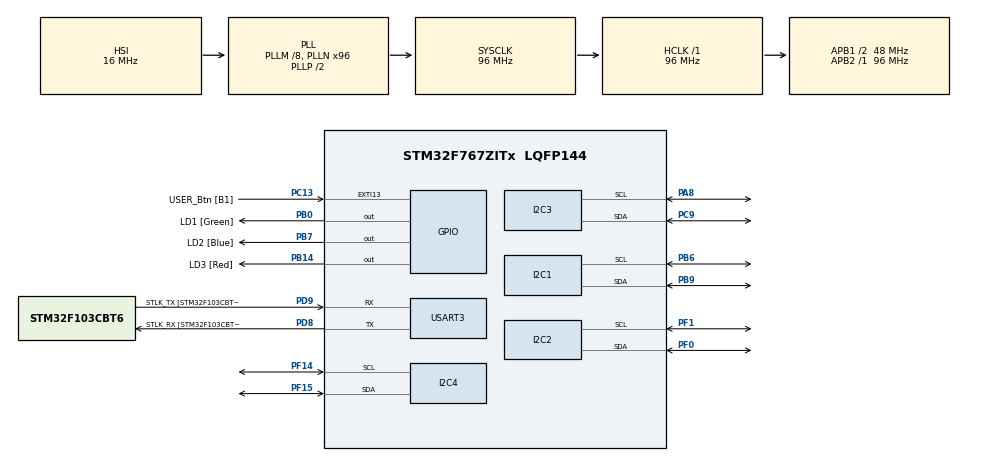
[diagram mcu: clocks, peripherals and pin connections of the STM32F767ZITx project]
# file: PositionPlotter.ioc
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CORTEX_M7.default_mode_Activation=1
Dma.I2C1_RX.0.Direction=DMA_PERIPH_TO_MEMORY
Dma.I2C1_RX.0.FIFOMode=DMA_FIFOMODE_DISABLE
Dma.I2C1_RX.0.Instance=DMA1_Stream0
Dma.I2C1_RX.0.MemDataAlignment=DMA_MDATAALIGN_BYTE
Dma.I2C1_RX.0.MemInc=DMA_MINC_ENABLE
Dma.I2C1_RX.0.Mode=DMA_NORMAL
Dma.I2C1_RX.0.PeriphDataAlignment=DMA_PDATAALIGN_BYTE
Dma.I2C1_RX.0.PeriphInc=DMA_PINC_DISABLE
Dma.I2C1_RX.0.Priority=DMA_PRIORITY_LOW
Dma.I2C2_RX.1.Direction=DMA_PERIPH_TO_MEMORY
Dma.I2C2_RX.1.FIFOMode=DMA_FIFOMODE_DISABLE
Dma.I2C2_RX.1.Instance=DMA1_Stream3
Dma.I2C2_RX.1.MemDataAlignment=DMA_MDATAALIGN_BYTE
Dma.I2C2_RX.1.MemInc=DMA_MINC_ENABLE
Dma.I2C2_RX.1.Mode=DMA_NORMAL
Dma.I2C2_RX.1.PeriphDataAlignment=DMA_PDATAALIGN_BYTE
Dma.I2C2_RX.1.PeriphInc=DMA_PINC_DISABLE
Dma.I2C2_RX.1.Priority=DMA_PRIORITY_LOW
Dma.I2C3_RX.2.Direction=DMA_PERIPH_TO_MEMORY
Dma.I2C3_RX.2.FIFOMode=DMA_FIFOMODE_DISABLE
Dma.I2C3_RX.2.Instance=DMA1_Stream2
Dma.I2C3_RX.2.MemDataAlignment=DMA_MDATAALIGN_BYTE
Dma.I2C3_RX.2.MemInc=DMA_MINC_ENABLE
Dma.I2C3_RX.2.Mode=DMA_NORMAL
Dma.I2C3_RX.2.PeriphDataAlignment=DMA_PDATAALIGN_BYTE
Dma.I2C3_RX.2.PeriphInc=DMA_PINC_DISABLE
Dma.I2C3_RX.2.Priority=DMA_PRIORITY_LOW
Dma.I2C4_RX.3.Direction=DMA_PERIPH_TO_MEMORY
Dma.I2C4_RX.3.FIFOMode=DMA_FIFOMODE_DISABLE
Dma.I2C4_RX.3.Instance=DMA1_Stream1
Dma.I2C4_RX.3.MemDataAlignment=DMA_MDATAALIGN_BYTE
Dma.I2C4_RX.3.MemInc=DMA_MINC_ENABLE
Dma.I2C4_RX.3.Mode=DMA_NORMAL
Dma.I2C4_RX.3.PeriphDataAlignment=DMA_PDATAALIGN_BYTE
Dma.I2C4_RX.3.PeriphInc=DMA_PINC_DISABLE
Dma.I2C4_RX.3.Priority=DMA_PRIORITY_LOW
Dma.Request0=I2C1_RX
Dma.Request1=I2C2_RX
Dma.Request2=I2C3_RX
Dma.Request3=I2C4_RX
I2C1.Timing=0x20303E5D
I2C2.Timing=0x20303E5D
I2C3.Timing=0x20303E5D
I2C4.Timing=0x20303E5D
Mcu.Family=STM32F7
Mcu.Name=STM32F767ZITx
Mcu.Package=LQFP144
NVIC.DMA1_Stream0_IRQn=true\:0\:0\:false\:false\:true\:false\:true\:true
NVIC.DMA1_Stream1_IRQn=true\:0\:0\:false\:false\:true\:false\:true\:true
NVIC.DMA1_Stream2_IRQn=true\:0\:0\:false\:false\:true\:false\:true\:true
NVIC.DMA1_Stream3_IRQn=true\:0\:0\:false\:false\:true\:false\:true\:true
NVIC.PriorityGroup=NVIC_PRIORITYGROUP_4
NVIC.TIM1_UP_TIM10_IRQn=true\:0\:0\:false\:false\:true\:true\:true\:true
PA8.Mode=I2C
PA8.Signal=I2C3_SCL
PB0.GPIO_Label=LD1 [Green]
PB0.Signal=GPIO_Output
PB14.GPIO_Label=LD3 [Red]
PB14.Signal=GPIO_Output
PB6.Mode=I2C
PB6.Signal=I2C1_SCL
PB7.GPIO_Label=LD2 [Blue]
PB7.Signal=GPIO_Output
PB9.Mode=I2C
PB9.Signal=I2C1_SDA
PC13.GPIO_Label=USER_Btn [B1]
PC13.Signal=GPXTI13
PC14/OSC32_IN.Mode=LSE-External-Oscillator
PC14/OSC32_IN.Signal=RCC_OSC32_IN
PC15/OSC32_OUT.Mode=LSE-External-Oscillator
PC15/OSC32_OUT.Signal=RCC_OSC32_OUT
PC9.Mode=I2C
PC9.Signal=I2C3_SDA
PD8.GPIO_Label=STLK_RX [STM32F103CBT6_PA3]
PD8.Mode=Asynchronous
PD8.Signal=USART3_TX
PD9.GPIO_Label=STLK_TX [STM32F103CBT6_PA2]
PD9.Mode=Asynchronous
PD9.Signal=USART3_RX
PF0.Mode=I2C
PF0.Signal=I2C2_SDA
PF1.Mode=I2C
PF1.Signal=I2C2_SCL
PF14.Mode=I2C
PF14.Signal=I2C4_SCL
PF15.Mode=I2C
PF15.Signal=I2C4_SDA
ProjectManager.HeapSize=0x200
ProjectManager.StackSize=0x400
ProjectManager.TargetToolchain=STM32CubeIDE
RCC.48MHZClocksFreq_Value=24000000
RCC.AHBFreq_Value=96000000
RCC.APB1CLKDivider=RCC_HCLK_DIV2
RCC.APB1Freq_Value=48000000
RCC.APB1TimFreq_Value=96000000
RCC.APB2Freq_Value=96000000
RCC.APB2TimFreq_Value=96000000
RCC.CortexFreq_Value=96000000
RCC.HCLKFreq_Value=96000000
RCC.HSE_VALUE=8000000
RCC.HSI_VALUE=16000000
RCC.PLLM=8
RCC.PLLMUL=RCC_PLL_MUL9
RCC.PLLN=96
RCC.PLLQ=4
RCC.PRESCALERUSB=RCC_USBCLKSOURCE_PLL_DIV1_5
RCC.SYSCLKFreq_VALUE=96000000
RCC.SYSCLKSource=RCC_SYSCLKSOURCE_PLLCLK
RCC.SYSCLKSourceVirtual=RCC_SYSCLKSOURCE_PLLCLK
RCC.USBFreq_Value=48000000
RCC.VCOOutputFreq_Value=192000000
USART3.VirtualMode-Asynchronous=VM_ASYNC
VP_TIM1_VS_ClockSourceINT.Mode=Internal
board=NUCLEO-F767ZI

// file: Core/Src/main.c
/* USER CODE BEGIN Header */
/**
  ******************************************************************************
  * @file           : main.c
  * @brief          : Main program body
  ******************************************************************************
  * @attention
  *
  * Copyright (c) 2026 STMicroelectronics.
  * All rights reserved.
  *
  * This software is licensed under terms that can be found in the LICENSE file
  * in the root directory of this software component.
  * If no LICENSE file comes with this software, it is provided AS-IS.
  *
  ******************************************************************************
  */
/* USER CODE END Header */
#include "main.h"
#include "dma.h"
#include "i2c.h"
#include "tim.h"
#include "usart.h"
#include "gpio.h"

/* USER CODE BEGIN Includes */
#include "encplot_main.h"
/* USER CODE END Includes */

void SystemClock_Config(void);
static void MPU_Config(void);

int main(void)
{

  /* MPU Configuration--------------------------------------------------------*/
  MPU_Config();

  /* MCU Configuration--------------------------------------------------------*/

  /* Reset of all peripherals, Initializes the Flash interface and the Systick. */
  HAL_Init();

  /* Configure the system clock */
  SystemClock_Config();

  /* Initialize all configured peripherals */
  MX_GPIO_Init();
  MX_DMA_Init();
  MX_I2C1_Init();
  MX_I2C2_Init();
  MX_I2C3_Init();
  MX_I2C4_Init();
  MX_USART3_UART_Init();
  MX_TIM1_Init();
  /* USER CODE BEGIN 2 */
  encplot_init();
  /* USER CODE END 2 */
  /* Infinite loop */
  /* USER CODE BEGIN WHILE */
  while (1)
  {
    encplot_loop();
    /* USER CODE END WHILE */

  }
}

void SystemClock_Config(void)
{
  RCC_OscInitTypeDef RCC_OscInitStruct = {0};
  RCC_ClkInitTypeDef RCC_ClkInitStruct = {0};

  /** Configure LSE Drive Capability
  */
  HAL_PWR_EnableBkUpAccess();

  /** Configure the main internal regulator output voltage
  */
  __HAL_RCC_PWR_CLK_ENABLE();
  __HAL_PWR_VOLTAGESCALING_CONFIG(PWR_REGULATOR_VOLTAGE_SCALE3);

  /** Initializes the RCC Oscillators according to the specified parameters
  * in the RCC_OscInitTypeDef structure.
  */
  RCC_OscInitStruct.OscillatorType = RCC_OSCILLATORTYPE_HSI;
  RCC_OscInitStruct.HSIState = RCC_HSI_ON;
  RCC_OscInitStruct.HSICalibrationValue = RCC_HSICALIBRATION_DEFAULT;
  RCC_OscInitStruct.PLL.PLLState = RCC_PLL_ON;
  RCC_OscInitStruct.PLL.PLLSource = RCC_PLLSOURCE_HSI;
  RCC_OscInitStruct.PLL.PLLM = 8;
  RCC_OscInitStruct.PLL.PLLN = 96;
  RCC_OscInitStruct.PLL.PLLP = RCC_PLLP_DIV2;
  RCC_OscInitStruct.PLL.PLLQ = 4;
  RCC_OscInitStruct.PLL.PLLR = 2;
  if (HAL_RCC_OscConfig(&RCC_OscInitStruct) != HAL_OK)
  {
    Error_Handler();
  }

  /** Activate the Over-Drive mode
  */
  if (HAL_PWREx_EnableOverDrive() != HAL_OK)
  {
    Error_Handler();
  }

  /** Initializes the CPU, AHB and APB buses clocks
  */
  RCC_ClkInitStruct.ClockType = RCC_CLOCKTYPE_HCLK|RCC_CLOCKTYPE_SYSCLK
                              |RCC_CLOCKTYPE_PCLK1|RCC_CLOCKTYPE_PCLK2;
  RCC_ClkInitStruct.SYSCLKSource = RCC_SYSCLKSOURCE_PLLCLK;
  RCC_ClkInitStruct.AHBCLKDivider = RCC_SYSCLK_DIV1;
  RCC_ClkInitStruct.APB1CLKDivider = RCC_HCLK_DIV2;
  RCC_ClkInitStruct.APB2CLKDivider = RCC_HCLK_DIV1;

  if (HAL_RCC_ClockConfig(&RCC_ClkInitStruct, FLASH_LATENCY_3) != HAL_OK)
  {
    Error_Handler();
  }
}

 /* MPU Configuration */

void MPU_Config(void)
{
  MPU_Region_InitTypeDef MPU_InitStruct = {0};

  /* Disables the MPU */
  HAL_MPU_Disable();

  /** Initializes and configures the Region and the memory to be protected
  */
  MPU_InitStruct.Enable = MPU_REGION_ENABLE;
  MPU_InitStruct.Number = MPU_REGION_NUMBER0;
  MPU_InitStruct.BaseAddress = 0x0;
  MPU_InitStruct.Size = MPU_REGION_SIZE_4GB;
  MPU_InitStruct.SubRegionDisable = 0x87;
  MPU_InitStruct.TypeExtField = MPU_TEX_LEVEL0;
  MPU_InitStruct.AccessPermission = MPU_REGION_NO_ACCESS;
  MPU_InitStruct.DisableExec = MPU_INSTRUCTION_ACCESS_DISABLE;
  MPU_InitStruct.IsShareable = MPU_ACCESS_SHAREABLE;
  MPU_InitStruct.IsCacheable = MPU_ACCESS_NOT_CACHEABLE;
  MPU_InitStruct.IsBufferable = MPU_ACCESS_NOT_BUFFERABLE;

  HAL_MPU_ConfigRegion(&MPU_InitStruct);
  /* Enables the MPU */
  HAL_MPU_Enable(MPU_PRIVILEGED_DEFAULT);

}

void Error_Handler(void)
{
  __disable_irq();
  while (1)
  {
  }
}
